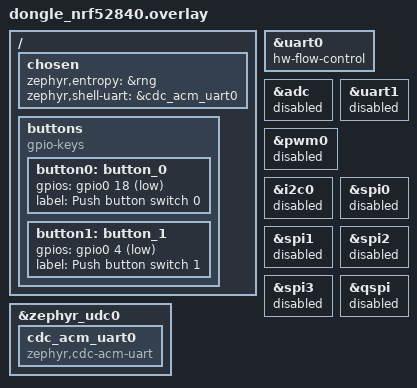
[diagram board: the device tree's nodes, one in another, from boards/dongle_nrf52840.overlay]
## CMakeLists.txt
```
#
# Copyright (c) 2020 Nordic Semiconductor ASA
#
# SPDX-License-Identifier: LicenseRef-Nordic-5-Clause
#

cmake_minimum_required(VERSION 3.20.0)

find_package(Zephyr REQUIRED HINTS $ENV{ZEPHYR_BASE})

project(thread_dongle_server_usb)

FILE(GLOB app_sources src/*.c)
# NORDIC SDK APP START
target_sources(app PRIVATE ${app_sources})

target_include_directories(app PRIVATE interface)
# NORDIC SDK APP END
```

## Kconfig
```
#
# Copyright (c) 2020 Nordic Semiconductor ASA
#
# SPDX-License-Identifier: LicenseRef-Nordic-5-Clause
#

menu "Zephyr Kernel"
source "Kconfig.zephyr"
endmenu

module = COAP_SERVER
module-str = CoAP server
source "${ZEPHYR_BASE}/subsys/logging/Kconfig.template.log_config"

module = OT_COAP_UTILS
module-str = OpenThread CoAP utils
source "${ZEPHYR_BASE}/subsys/logging/Kconfig.template.log_config"

config UART_LOG_ENABLE
    bool "Enable UART logging"
    default n
    help
      Enable this option to activate logging over UART
```

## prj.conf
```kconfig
#
# Copyright (c) 2020 Nordic Semiconductor
#
# SPDX-License-Identifier: LicenseRef-Nordic-5-Clause
#

# nRF board library
CONFIG_DK_LIBRARY=y 

# Enable OpenThread CoAP support API
CONFIG_OPENTHREAD_COAP=y 

# Network sockets
CONFIG_NET_SOCKETS=y
CONFIG_NET_SOCKETS_POSIX_NAMES=y
CONFIG_NET_SOCKETS_POLL_MAX=4

# Same network Master Key for client and server
CONFIG_OPENTHREAD_NETWORKKEY="00:11:22:33:44:55:66:77:88:99:aa:bb:cc:dd:ee:ff"

# L2 OpenThread enabling
CONFIG_NET_L2_OPENTHREAD=y

# Generic networking options
CONFIG_NETWORKING=y

CONFIG_MBEDTLS_SHA1_C=n
CONFIG_FPU=y

# UART conf
CONFIG_SERIAL=y
CONFIG_UART_INTERRUPT_DRIVEN=y
CONFIG_UART_ASYNC_API=y
CONFIG_UART_LOG_ENABLE=n
```

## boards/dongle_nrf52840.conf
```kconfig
#
# Copyright (c) 2016-2023 Makerdiary
#
# SPDX-License-Identifier: Apache-2.0
#

# USB subsystem configuration
CONFIG_USB_DEVICE_STACK=y
CONFIG_USB_DEVICE_PRODUCT="Thread Border Router USB"
CONFIG_USB_DEVICE_INITIALIZE_AT_BOOT=y
```

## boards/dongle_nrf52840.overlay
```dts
/* Copyright (c) 2020 Nordic Semiconductor ASA
 *
 * SPDX-License-Identifier: LicenseRef-Nordic-5-Clause
 */

&uart0 {
    status = "okay";
    hw-flow-control;
};

&zephyr_udc0 {
    cdc_acm_uart0: cdc_acm_uart0 {
        compatible = "zephyr,cdc-acm-uart";
    };
};

/ {
    /*
    * In some default configurations within the nRF Connect SDK,
    * e.g. on nRF52840, the chosen zephyr,entropy node is &cryptocell.
    * This devicetree overlay ensures that default is overridden wherever it
    * is set, as this application uses the RNG node for entropy exclusively.
    */
    chosen {
        zephyr,entropy = &rng;
        zephyr,shell-uart = &cdc_acm_uart0;
    };
    buttons {
        compatible = "gpio-keys";
        button0: button_0 {
            gpios = <&gpio0 18 (GPIO_PULL_UP | GPIO_ACTIVE_LOW)>;
            label = "Push button switch 0";
        };
        button1: button_1 {
            gpios = <&gpio0 4 (GPIO_PULL_UP | GPIO_ACTIVE_LOW)>;
            label = "Push button switch 1";
        };
    };
};

&adc {
    status = "disabled";
};
&uart1 {
    status = "disabled";
};
&pwm0 {
    status = "disabled";
};
&i2c0 {
    status = "disabled";
};
&spi0 {
    status = "disabled";
};
&spi1 {
    status = "disabled";
};
&spi2 {
    status = "disabled";
};
&spi3 {
    status = "disabled";
};
&qspi {
    status = "disabled";
};
```

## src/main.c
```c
/*
 * Copyright (c) 2020 Nordic Semiconductor ASA
 * Copyright (c) 2016-2023 Makerdiary
 *
 * SPDX-License-Identifier: LicenseRef-Nordic-5-Clause
 */

#include <zephyr/kernel.h>
#include <dk_buttons_and_leds.h>

#include "coap_server.h"
#include "uart_interface.h"

#define SLEEP_TIME_MS   100

//Callback for button press
static void on_button_changed(uint32_t button_state, uint32_t has_changed)
{
    // TODO: What to do if button pressed ???
    uint32_t buttons = button_state & has_changed;
    if (buttons & DK_BTN1_MSK) {
        print_ressources_status();
        //  switch_wifi_status();
        //  switch_presence_status();
        //  switch_electrical_status();
    }    
}

int main(void)
{   int ret;

    ret = init_uart();
    if (ret) {
        print_uart("[ERROR]: UART init \r\n");
        return 1;
    } 
    print_uart("[LOG]: UART initialized\r\n");

    print_uart("[LOG]: Green WiFi Thread Dongle .\r\n");
	print_uart("[LOG]: Developed by Nicolas Hernandez\r\n");
    print_uart("[LOG]: nicolas.hernandez@orange.com\r\n");

    ret = dk_leds_init();
    if (ret) {
        print_uart("[ERROR]: leds init \r\n");
        return 1;
    }
    print_uart("[LOG]: Leds initialized\r\n");

    ret = dk_buttons_init(on_button_changed);
    if (ret) {
        print_uart("[ERROR]: buttons init \r\n");
        return 1;
    }
    print_uart("[LOG]: Butttons initialized\r\n");

    ret = init_coap_thread();
    if (ret) {
        print_uart("[ERROR]: Thread init \r\n");
        return 1;
    }    
    print_uart("[LOG]: Thread initialized\r\n");

    // loop forever waiting for uart messages
    read_forever();
    return 0;
}
```

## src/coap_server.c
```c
/*
 * Copyright (c) 2020 Nordic Semiconductor ASA
 * Copyright (c) 2016-2023 Makerdiary
 *
 * SPDX-License-Identifier: LicenseRef-Nordic-5-Clause
 */

#include "ot_coap_utils.h"

#define LED_ON_TIME_MS 250
char uart_print_buff[50]; 

// Callback for commands topic
static void on_commands_request(uint8_t* msg_buf, uint8_t msg_len)
{   
    // Empty the string
    uart_print_buff[0] = '\0';

    print_uart("[LOG]: COAP - Commands msg received: ");
    for (int i = 0; i <= msg_len; i++) {
        uart_print_buff[i] = msg_buf[i];
    }
    uart_print_buff[msg_len] = '\0';
    print_uart(uart_print_buff);

    dk_set_led_on(COMMANDS_MSG_LED);
    k_msleep(LED_ON_TIME_MS);
    dk_set_led_off(COMMANDS_MSG_LED);  
    
}

// Callback for ressources status topic
static void on_ressource_status_request()
{
    dk_set_led_on(RESSOURCES_STATUS_MSG_LED);
    k_msleep(LED_ON_TIME_MS);
    dk_set_led_off(RESSOURCES_STATUS_MSG_LED);    
}

// Callback for wifi topic
static void on_wifi_status_request()
{
    dk_set_led_on(RESSOURCES_STATUS_MSG_LED);
    k_msleep(LED_ON_TIME_MS);
    dk_set_led_off(RESSOURCES_STATUS_MSG_LED);    
}

// Callback for presence topic
static void on_presence_status_request()
{
    dk_set_led_on(RESSOURCES_STATUS_MSG_LED);
    k_msleep(LED_ON_TIME_MS);
    dk_set_led_off(RESSOURCES_STATUS_MSG_LED);    
}

// Callback for electrical topic
static void on_electrical_status_request()
{
    dk_set_led_on(RESSOURCES_STATUS_MSG_LED);
    k_msleep(LED_ON_TIME_MS);
    dk_set_led_off(RESSOURCES_STATUS_MSG_LED);    
}

// Callback for power strip topic
static void on_power_strip_status_request()
{
    dk_set_led_on(RESSOURCES_STATUS_MSG_LED);
    k_msleep(LED_ON_TIME_MS);
    dk_set_led_off(RESSOURCES_STATUS_MSG_LED);    
}

static void on_thread_state_changed(otChangedFlags flags, struct openthread_context *ot_context,
                    void *user_data)
{
    if (flags & OT_CHANGED_THREAD_ROLE) {
        switch (otThreadGetDeviceRole(ot_context->instance)) {
        case OT_DEVICE_ROLE_CHILD:
        case OT_DEVICE_ROLE_ROUTER:
        case OT_DEVICE_ROLE_LEADER:
            dk_set_led_on(OT_CONNECTION_LED);
            break;

        case OT_DEVICE_ROLE_DISABLED:
        case OT_DEVICE_ROLE_DETACHED:
        default:
            dk_set_led_off(OT_CONNECTION_LED);
            break;
        }
    }
}

static struct openthread_state_changed_cb ot_state_chaged_cb = { .state_changed_cb =
                                     on_thread_state_changed };


int init_coap_thread()
{
    int ret;
    ret = ot_coap_init(
        &on_ressource_status_request, 
        &on_wifi_status_request, 
        &on_presence_status_request, 
        &on_electrical_status_request, 
        &on_power_strip_status_request, 
        &on_commands_request
    );
    
    if (ret) {
        print_uart("[ERROR]: Init OpenThread CoAP\r\n: ");
        return 1;
    }

    openthread_state_changed_cb_register(openthread_get_default_context(), &ot_state_chaged_cb);
    openthread_start(openthread_get_default_context());    

    return 0;

}
```

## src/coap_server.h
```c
#ifndef COAP_SERVER_H
#define COAP_SERVER_H

#include <zephyr/net/openthread.h>
#include <openthread/thread.h>
#include <zephyr/kernel.h>
#include <dk_buttons_and_leds.h>

// Function declarations
static void on_commands_request(uint8_t* msg_buf, uint8_t msg_len);
static void on_ressource_status_request(void);
static void on_wifi_status_request(void);
static void on_presence_status_request(void);
static void on_electrical_status_request(void);
static void on_power_strip_status_request();
static void on_thread_state_changed(otChangedFlags flags, struct openthread_context *ot_context, void *user_data);
int init_coap_thread();

#endif 
```

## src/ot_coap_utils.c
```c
/*
 * Copyright (c) 2020 Nordic Semiconductor ASA
 *
 * SPDX-License-Identifier: LicenseRef-Nordic-5-Clause
 */

#include "ot_coap_utils.h"
#include "uart_interface.h"

uint8_t msg_buf[MSG_BUFF_SIZE];
uint16_t msg_len = 0; 
char print_buff[50]; 

struct server_context {
    struct otInstance *ot;
    ressources_status_request_callback_t on_ressources_status_request;
    wifi_status_request_callback_t on_wifi_status_request;
    presence_status_request_callback_t on_presence_status_request;
    electrical_status_request_callback_t on_eletrical_status_request;
    power_strip_status_request_callback_t on_power_strip_status_request;
    commands_request_callback_t on_commands_request;
    bool wifi_status;
    bool presence_status;
    bool electrical_status;
    bool power_strip_r1_status;
    bool power_strip_r2_status;
    bool power_strip_r3_status;
    bool power_strip_r4_status;
};

static struct server_context srv_context = {
    .ot = NULL,    
    .on_ressources_status_request = NULL,
    .on_wifi_status_request = NULL,
    .on_eletrical_status_request= NULL,
    .on_commands_request = NULL,
    .wifi_status = NULL,
    .presence_status = NULL,
    .electrical_status = NULL,
    .power_strip_r1_status = NULL,
    .power_strip_r2_status = NULL,
    .power_strip_r3_status = NULL,
    .power_strip_r4_status = NULL,
};

/**@brief Definition of CoAP resources for orchestrator status resources. */
static otCoapResource ressources_status_resource = {
    .mUriPath = RESSOURCES_URI_PATH,
    .mHandler = NULL,
    .mContext = NULL,
    .mNext = NULL,
};

/**@brief Definition of CoAP resources for wifi status resources. */
static otCoapResource wifi_status_resource = {
    .mUriPath = WIFI_URI_PATH,
    .mHandler = NULL,
    .mContext = NULL,
    .mNext = NULL,
};

/**@brief Definition of CoAP resources for presence status resources. */
static otCoapResource presence_status_resource = {
    .mUriPath = PRESENCE_URI_PATH,
    .mHandler = NULL,
    .mContext = NULL,
    .mNext = NULL,
};

/**@brief Definition of CoAP resources for electrical status resources. */
static otCoapResource electrical_status_resource = {
    .mUriPath = ELECTRIC_URI_PATH,
    .mHandler = NULL,
    .mContext = NULL,
    .mNext = NULL,
};

/**@brief Definition of CoAP resources for power_strip status resources. */
static otCoapResource power_strip_status_resource = {
    .mUriPath = POWER_STRIP_URI_PATH,
    .mHandler = NULL,
    .mContext = NULL,
    .mNext = NULL,
};

/**@brief Definition of CoAP resources for commands. */
static otCoapResource commands_resource = {
    .mUriPath = COMMANDS_URI_PATH,
    .mHandler = NULL,
    .mContext = NULL,
    .mNext = NULL,
};

void set_wifi_status(bool new_status){
    srv_context.wifi_status = new_status;
    snprintf(print_buff, sizeof(print_buff), "%s%s\r\n", "[LOG]: New wifi status ", srv_context.wifi_status ? "true" : "false");
    print_uart(print_buff);
}
void set_presence_status(bool new_status){
    srv_context.presence_status = new_status;
    snprintf(print_buff, sizeof(print_buff), "%s%s\r\n", "[LOG]: New presence status ", srv_context.presence_status ? "true" : "false");
    print_uart(print_buff);
}
void set_electrical_status(bool new_status){
    srv_context.electrical_status = new_status;
    snprintf(print_buff, sizeof(print_buff), "%s%s\r\n", "[LOG]: New electrical status ", srv_context.electrical_status ? "true" : "false");
    print_uart(print_buff);
}

void set_power_strip_status(bool new_r1_status, bool new_r2_status, bool new_r3_status, bool new_r4_status){
    srv_context.power_strip_r1_status = new_r1_status;
    srv_context.power_strip_r2_status = new_r2_status;
    srv_context.power_strip_r3_status = new_r3_status;
    srv_context.power_strip_r4_status = new_r4_status;
    snprintf(print_buff, sizeof(print_buff), "%s%d%d%d%d\r\n", "[LOG]: New power strip status ", srv_context.power_strip_r1_status, srv_context.power_strip_r2_status, srv_context.power_strip_r3_status, srv_context.power_strip_r4_status );
    print_uart(print_buff);
}

void print_ressources_status(void){
    print_uart("[LOG]: Server Ressources   \r\n");
    snprintf(print_buff, sizeof(print_buff), "%s%s\r\n", "[LOG]:     Wifi status ", srv_context.wifi_status ? "true" : "false");
    print_uart(print_buff);     
    snprintf(print_buff, sizeof(print_buff), "%s%s\r\n", "[LOG]:     Presence status ", srv_context.presence_status ? "true" : "false");
    print_uart(print_buff);
    snprintf(print_buff, sizeof(print_buff), "%s%s\r\n", "[LOG]:     Electrical status ", srv_context.electrical_status ? "true" : "false");
    print_uart(print_buff);
    snprintf(print_buff, sizeof(print_buff), "%s%d%d%d%d\r\n", "[LOG]:     Power strip status ", srv_context.power_strip_r1_status, srv_context.power_strip_r2_status, srv_context.power_strip_r3_status, srv_context.power_strip_r4_status );
    print_uart(print_buff);
}

static otError ressources_status_response_send(otMessage *request_message,
                      const otMessageInfo *message_info)
{
    otError error = OT_ERROR_NO_BUFS;
    otMessage *response;    

    response = otCoapNewMessage(srv_context.ot, NULL);
    if (response == NULL) {
        goto end;
    }

    otCoapMessageInit(response, OT_COAP_TYPE_NON_CONFIRMABLE,
              OT_COAP_CODE_CONTENT);

    error = otCoapMessageSetToken(
        response, otCoapMessageGetToken(request_message),
        otCoapMessageGetTokenLength(request_message));
    if (error != OT_ERROR_NONE) {
        goto end;
    }

    error = otCoapMessageSetPayloadMarker(response);
    if (error != OT_ERROR_NONE) {
        goto end;
    }

    // Append wifi status to payload
    uint8_t *wifi_payload = srv_context.wifi_status ? "wifi:1" : "wifi:0";
    uint16_t wifi_payload_size = strlen(wifi_payload);
    
    // Append ressources status to payload
    uint8_t *presence_payload = srv_context.presence_status ? " prs:1" : " prs:0";
    uint16_t presence_payload_size = strlen(presence_payload);

    // Append electrical status to payload
    uint8_t *electrical_payload = srv_context.electrical_status ? " ele:1" : " ele:0";
    uint16_t electrical_payload_size = strlen(electrical_payload);

    // Append power strip status to payload  
    uint8_t power_strip_payload[] = " outlet:XXXX";
    uint8_t r1_status_payload = srv_context.power_strip_r1_status ? '1':'0';
    uint8_t r2_status_payload = srv_context.power_strip_r2_status ? '1':'0';
    uint8_t r3_status_payload = srv_context.power_strip_r3_status ? '1':'0';
    uint8_t r4_status_payload = srv_context.power_strip_r4_status ? '1':'0';
    power_strip_payload[8] = r1_status_payload;   
    power_strip_payload[9] = r2_status_payload;   
    power_strip_payload[10] = r3_status_payload;   
    power_strip_payload[11] = r4_status_payload;   
    uint16_t power_strip_payload_size = strlen(power_strip_payload);

    // Get payload size
    uint16_t payload_size = wifi_payload_size + presence_payload_size + electrical_payload_size + power_strip_payload_size + 1;
    uint8_t *payload = (uint8_t*) malloc(payload_size * sizeof(uint8_t));

    if(payload == NULL) {
        print_uart("[ERROR]: Error in payload memory alocation \r\n");    
        error = OT_ERROR_FAILED; 
        goto end;
    }

    // Concatenate payload
    uint16_t new_index = 0;
    for(uint16_t i = 0; i < payload_size - 1; i++){
        if(i < wifi_payload_size){   
            payload[i] = wifi_payload[i];
        }
        if((i >= wifi_payload_size) && (i < wifi_payload_size + presence_payload_size)){
            new_index = i - wifi_payload_size;
            payload[i] = presence_payload[new_index];
        }
        if((i >= wifi_payload_size + presence_payload_size) && (i < wifi_payload_size + presence_payload_size + electrical_payload_size)){
            new_index = i - wifi_payload_size - presence_payload_size;
            payload[i] = electrical_payload[new_index];
        }
        if(i >= wifi_payload_size + presence_payload_size + electrical_payload_size){   
            new_index = i - wifi_payload_size - presence_payload_size - electrical_payload_size;
            payload[i] = power_strip_payload[new_index];
        }
    }

    payload[payload_size - 1 ] = '\0';
    snprintf(print_buff, sizeof(print_buff), "%s%s\r\n", "[LOG]: Sending response payload: ", payload);
    print_uart(print_buff);

    error = otMessageAppend(response, payload, payload_size);
    if (error != OT_ERROR_NONE) {
        goto end;
    }

    error = otCoapSendResponse(srv_context.ot, response, message_info);

end:
    if (error != OT_ERROR_NONE && response != NULL) {
        otMessageFree(response);
    }

    free(payload);
    return error;
}

static void ressources_status_request_handler(void *context, otMessage *message,
                     const otMessageInfo *message_info)
{
    otError error;
    otMessageInfo msg_info;

    ARG_UNUSED(context);
    
    print_uart("[LOG]: Received ressources status request\r\n");

    if ((otCoapMessageGetType(message) == OT_COAP_TYPE_NON_CONFIRMABLE) &&
        (otCoapMessageGetCode(message) == OT_COAP_CODE_GET)) {
        msg_info = *message_info;
        memset(&msg_info.mSockAddr, 0, sizeof(msg_info.mSockAddr));

        error = ressources_status_response_send(message, &msg_info);
        if (error == OT_ERROR_NONE) {
            srv_context.on_ressources_status_request();
        }
    }
}

static otError wifi_status_response_send(otMessage *request_message,
                      const otMessageInfo *message_info)
{
    otError error = OT_ERROR_NO_BUFS;
    otMessage *response;    

    response = otCoapNewMessage(srv_context.ot, NULL);
    if (response == NULL) {
        goto end;
    }

    otCoapMessageInit(response, OT_COAP_TYPE_NON_CONFIRMABLE,
              OT_COAP_CODE_CONTENT);

    error = otCoapMessageSetToken(
        response, otCoapMessageGetToken(request_message),
        otCoapMessageGetTokenLength(request_message));
    if (error != OT_ERROR_NONE) {
        goto end;
    }

    error = otCoapMessageSetPayloadMarker(response);
    if (error != OT_ERROR_NONE) {
        goto end;
    }

    // Append wifi status to payload
    uint8_t *payload = srv_context.wifi_status ? "wifi:1" : "wifi:0";
    uint16_t payload_size = strlen(payload) + 1;

    snprintf(print_buff, sizeof(print_buff), "%s%s\r\n", "[LOG]: Wifi response payload: ", payload);
    print_uart(print_buff);

    error = otMessageAppend(response, payload, payload_size);
    if (error != OT_ERROR_NONE) {
        goto end;
    }

    error = otCoapSendResponse(srv_context.ot, response, message_info);

end:
    if (error != OT_ERROR_NONE && response != NULL) {
        otMessageFree(response);
    }

    return error;
}

static void wifi_status_request_handler(void *context, otMessage *message,
                     const otMessageInfo *message_info)
{
    otError error;
    otMessageInfo msg_info;

    ARG_UNUSED(context);

    print_uart("LOG]: Received wifi status request\r\n");

    if ((otCoapMessageGetType(message) == OT_COAP_TYPE_NON_CONFIRMABLE) &&
        (otCoapMessageGetCode(message) == OT_COAP_CODE_GET)) {
        msg_info = *message_info;
        memset(&msg_info.mSockAddr, 0, sizeof(msg_info.mSockAddr));

        error = wifi_status_response_send(message, &msg_info);
        if (error == OT_ERROR_NONE) {
            srv_context.on_ressources_status_request();
        }
    }
}

static otError presence_status_response_send(otMessage *request_message,
                      const otMessageInfo *message_info)
{
    otError error = OT_ERROR_NO_BUFS;
    otMessage *response;    

    response = otCoapNewMessage(srv_context.ot, NULL);
    if (response == NULL) {
        goto end;
    }

    otCoapMessageInit(response, OT_COAP_TYPE_NON_CONFIRMABLE,
              OT_COAP_CODE_CONTENT);

    error = otCoapMessageSetToken(
        response, otCoapMessageGetToken(request_message),
        otCoapMessageGetTokenLength(request_message));
    if (error != OT_ERROR_NONE) {
        goto end;
    }

    error = otCoapMessageSetPayloadMarker(response);
    if (error != OT_ERROR_NONE) {
        goto end;
    }

    // Append presence status to payload
    uint8_t *payload = srv_context.presence_status ? "prs:1" : "prs:0";
    uint16_t payload_size = strlen(payload) + 1;

    snprintf(print_buff, sizeof(print_buff), "%s%s\r\n", "[LOG]: Presence response payload: ", payload);
    print_uart(print_buff);

    error = otMessageAppend(response, payload, payload_size);
    if (error != OT_ERROR_NONE) {
        goto end;
    }

    error = otCoapSendResponse(srv_context.ot, response, message_info);

end:
    if (error != OT_ERROR_NONE && response != NULL) {
        otMessageFree(response);
    }

    return error;
}

static void presence_status_request_handler(void *context, otMessage *message,
                     const otMessageInfo *message_info)
{
    otError error;
    otMessageInfo msg_info;

    ARG_UNUSED(context);

    print_uart("[LOG]: Received presence status request\r\n");

    if ((otCoapMessageGetType(message) == OT_COAP_TYPE_NON_CONFIRMABLE) &&
        (otCoapMessageGetCode(message) == OT_COAP_CODE_GET)) {
        msg_info = *message_info;
        memset(&msg_info.mSockAddr, 0, sizeof(msg_info.mSockAddr));

        error = presence_status_response_send(message, &msg_info);
        if (error == OT_ERROR_NONE) {
            srv_context.on_ressources_status_request();
        }
    }
}

static otError electrical_status_response_send(otMessage *request_message,
                      const otMessageInfo *message_info)
{
    otError error = OT_ERROR_NO_BUFS;
    otMessage *response;    

    response = otCoapNewMessage(srv_context.ot, NULL);
    if (response == NULL) {
        goto end;
    }

    otCoapMessageInit(response, OT_COAP_TYPE_NON_CONFIRMABLE,
              OT_COAP_CODE_CONTENT);

    error = otCoapMessageSetToken(
        response, otCoapMessageGetToken(request_message),
        otCoapMessageGetTokenLength(request_message));
    if (error != OT_ERROR_NONE) {
        goto end;
    }

    error = otCoapMessageSetPayloadMarker(response);
    if (error != OT_ERROR_NONE) {
        goto end;
    }

    // Append electrical status to payload
    uint8_t *payload = srv_context.electrical_status ? "ele:1" : "ele:0";
    uint16_t payload_size = strlen(payload) + 1;

    snprintf(print_buff, sizeof(print_buff), "%s%s\r\n", "[LOG]: Electrical response payload: ", payload);
    print_uart(print_buff);

    error = otMessageAppend(response, payload, payload_size);
    if (error != OT_ERROR_NONE) {
        goto end;
    }

    error = otCoapSendResponse(srv_context.ot, response, message_info);

end:
    if (error != OT_ERROR_NONE && response != NULL) {
        otMessageFree(response);
    }

    return error;
}

static void electrical_status_request_handler(void *context, otMessage *message,
                     const otMessageInfo *message_info)
{
    otError error;
    otMessageInfo msg_info;

    ARG_UNUSED(context);

    print_uart("[LOG]: Received electrical status request\r\n");

    if ((otCoapMessageGetType(message) == OT_COAP_TYPE_NON_CONFIRMABLE) &&
        (otCoapMessageGetCode(message) == OT_COAP_CODE_GET)) {
        msg_info = *message_info;
        memset(&msg_info.mSockAddr, 0, sizeof(msg_info.mSockAddr));

        error = electrical_status_response_send(message, &msg_info);
        if (error == OT_ERROR_NONE) {
            srv_context.on_ressources_status_request();
        }
    }
}

static otError power_strip_status_response_send(otMessage *request_message,
                      const otMessageInfo *message_info)
{
    otError error = OT_ERROR_NO_BUFS;
    otMessage *response;    

    response = otCoapNewMessage(srv_context.ot, NULL);
    if (response == NULL) {
        goto end;
    }

    otCoapMessageInit(response, OT_COAP_TYPE_NON_CONFIRMABLE,
              OT_COAP_CODE_CONTENT);

    error = otCoapMessageSetToken(
        response, otCoapMessageGetToken(request_message),
        otCoapMessageGetTokenLength(request_message));
    if (error != OT_ERROR_NONE) {
        goto end;
    }

    error = otCoapMessageSetPayloadMarker(response);
    if (error != OT_ERROR_NONE) {
        goto end;
    }

    // Append power strip status to payload
    uint8_t payload[] = " outlet:XXXX";
    payload[8] = srv_context.power_strip_r1_status ? '1':'0';   
    payload[9] = srv_context.power_strip_r2_status ? '1':'0';   
    payload[10] = srv_context.power_strip_r3_status ? '1':'0';   
    payload[11] = srv_context.power_strip_r4_status ? '1':'0';   
    uint16_t payload_size = strlen(payload);    

    snprintf(print_buff, sizeof(print_buff), "%s%s\r\n", "[LOG]: Power Strip response payload: ", payload);
    print_uart(print_buff);

    error = otMessageAppend(response, payload, payload_size);
    if (error != OT_ERROR_NONE) {
        goto end;
    }

    error = otCoapSendResponse(srv_context.ot, response, message_info);

end:
    if (error != OT_ERROR_NONE && response != NULL) {
        otMessageFree(response);
    }

    return error;
}

static void power_strip_status_request_handler(void *context, otMessage *message,
                     const otMessageInfo *message_info)
{
    otError error;
    otMessageInfo msg_info;

    ARG_UNUSED(context);

    print_uart("[LOG]: Received power strip status request\r\n");

    if ((otCoapMessageGetType(message) == OT_COAP_TYPE_NON_CONFIRMABLE) &&
        (otCoapMessageGetCode(message) == OT_COAP_CODE_GET)) {
        msg_info = *message_info;
        memset(&msg_info.mSockAddr, 0, sizeof(msg_info.mSockAddr));

        error = power_strip_status_response_send(message, &msg_info);
        if (error == OT_ERROR_NONE) {
            srv_context.on_ressources_status_request();
        }
    }
}

static otError commands_msg_response_send(otMessage *request_message,
                      const otMessageInfo *message_info)
{
    otError error = OT_ERROR_NO_BUFS;
    otMessage *response;    

    response = otCoapNewMessage(srv_context.ot, NULL);
    if (response == NULL) {
        goto end;
    }

    otCoapMessageInit(response, OT_COAP_TYPE_NON_CONFIRMABLE,
              OT_COAP_CODE_CONTENT);

    error = otCoapMessageSetToken(
        response, otCoapMessageGetToken(request_message),
        otCoapMessageGetTokenLength(request_message));
    if (error != OT_ERROR_NONE) {
        goto end;
    }

    error = otCoapMessageSetPayloadMarker(response);
    if (error != OT_ERROR_NONE) {
        goto end;
    }

    // Append presence status to payload
    uint8_t *payload = "CMD:OK";
    uint16_t payload_size = strlen(payload) + 1;

    error = otMessageAppend(response, payload, payload_size);
    if (error != OT_ERROR_NONE) {
        goto end;
    }

    error = otCoapSendResponse(srv_context.ot, response, message_info);

end:
    if (error != OT_ERROR_NONE && response != NULL) {
        otMessageFree(response);
    }

    return error;
}

static void commands_request_handler(void *context, otMessage *message,
                  const otMessageInfo *message_info)
{

    otError error;
    otMessageInfo msg_info;

    ARG_UNUSED(context);

    print_uart("[LOG]: Commands message received\r\n");

    ARG_UNUSED(context);   

    if (otCoapMessageGetType(message) != OT_COAP_TYPE_NON_CONFIRMABLE) {
        print_uart("[ERROR]: Commands handler - Unexpected type of message\r\n");
        goto end;
    }

    if (otCoapMessageGetCode(message) != OT_COAP_CODE_PUT) {
        print_uart("[ERROR]: Commands handler - Unexpected CoAP code\r\n");
        goto end;
    }

    msg_info = *message_info;
    memset(&msg_info.mSockAddr, 0, sizeof(msg_info.mSockAddr));

    error = commands_msg_response_send(message, &msg_info);
    if (error == OT_ERROR_NONE) {
        msg_len = otMessageRead(message, otMessageGetOffset(message), msg_buf, MSG_BUFF_SIZE);
        srv_context.on_commands_request(&msg_buf, msg_len);
    }   
end:
    return;
}

static void coap_default_handler(void *context, otMessage *message,
                 const otMessageInfo *message_info)
{
    print_uart("[LOG]: Uncontext msg received\r\n");
    ARG_UNUSED(context);
    ARG_UNUSED(message);
    ARG_UNUSED(message_info);
}

int ot_coap_init(
    ressources_status_request_callback_t on_ressources_status_request,
    wifi_status_request_callback_t on_wifi_status_request,
    presence_status_request_callback_t on_presence_status_request,
    electrical_status_request_callback_t on_electrical_status_request,
    power_strip_status_request_callback_t on_power_strip_status_request,
    commands_request_callback_t on_commands_request  
)
{
    otError error;

    srv_context.wifi_status = false;
    srv_context.presence_status = false;
    srv_context.electrical_status = false;

    srv_context.on_ressources_status_request = on_ressources_status_request;
    srv_context.on_wifi_status_request = on_wifi_status_request;
    srv_context.on_presence_status_request = on_presence_status_request;
    srv_context.on_eletrical_status_request = on_electrical_status_request;
    srv_context.on_power_strip_status_request = on_power_strip_status_request;
    srv_context.on_commands_request = on_commands_request;    

    srv_context.ot = openthread_get_default_instance();
    if (!srv_context.ot) {
        error = OT_ERROR_FAILED;
        goto end;
    }

    ressources_status_resource.mContext = srv_context.ot;
    ressources_status_resource.mHandler = ressources_status_request_handler;

    wifi_status_resource.mContext = srv_context.ot;
    wifi_status_resource.mHandler = wifi_status_request_handler;

    presence_status_resource.mContext = srv_context.ot;
    presence_status_resource.mHandler = presence_status_request_handler;

    electrical_status_resource.mContext = srv_context.ot;
    electrical_status_resource.mHandler = electrical_status_request_handler;

    power_strip_status_resource.mContext = srv_context.ot;
    power_strip_status_resource.mHandler = power_strip_status_request_handler;

    commands_resource.mContext = srv_context.ot;
    commands_resource.mHandler = commands_request_handler;

    otCoapSetDefaultHandler(srv_context.ot, coap_default_handler, NULL);
    otCoapAddResource(srv_context.ot, &commands_resource);
    otCoapAddResource(srv_context.ot, &ressources_status_resource);
    otCoapAddResource(srv_context.ot, &wifi_status_resource);
    otCoapAddResource(srv_context.ot, &presence_status_resource);
    otCoapAddResource(srv_context.ot, &electrical_status_resource);
    otCoapAddResource(srv_context.ot, &power_strip_status_resource);

    error = otCoapStart(srv_context.ot, COAP_PORT);
    if (error != OT_ERROR_NONE) {
        goto end;
    }

end:
    return error == OT_ERROR_NONE ? 0 : 1;
}
```

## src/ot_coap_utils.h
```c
/*
 * Copyright (c) 2020 Nordic Semiconductor ASA
 *
 * SPDX-License-Identifier: LicenseRef-Nordic-5-Clause
 */

#ifndef __OT_COAP_UTILS_H__
#define __OT_COAP_UTILS_H__

#include <thread_dongle_interface.h>
#include <zephyr/net/net_pkt.h>
#include <zephyr/net/net_l2.h>
#include <zephyr/net/openthread.h>
#include <openthread/coap.h>
#include <openthread/ip6.h>
#include <openthread/message.h>
#include <openthread/thread.h>

/**@brief Type definition of the function used to handle commands resource msg.
 */
typedef void (*commands_request_callback_t)(uint8_t* msg_buf, uint8_t msg_len);
/**@brief Type definition of the function used to handle ressources status resource msg.
 */
typedef void (*ressources_status_request_callback_t)();
/**@brief Type definition of the function used to handle wifi status resource msg.
 */
typedef void (*wifi_status_request_callback_t)();
/**@brief Type definition of the function used to handle presence status resource msg.
 */
typedef void (*presence_status_request_callback_t)();

/**@brief Type definition of the function used to handle electrical status resource msg.
 */
typedef void (*electrical_status_request_callback_t)();

/**@brief Type definition of the function used to handle power strip status resource msg.
 */
typedef void (*power_strip_status_request_callback_t)();

int ot_coap_init(
    ressources_status_request_callback_t on_ressources_status_request, 
    wifi_status_request_callback_t on_wifi_status_request, 
    presence_status_request_callback_t on_presence_status_request,
    electrical_status_request_callback_t on_electrical_status_request, 
    power_strip_status_request_callback_t on_power_strip_status_request, 
    commands_request_callback_t on_commands_request
);

/**@brief Type definition of the function used to set wifi status resource msg.
 */
void set_wifi_status(bool new_status);
/**@brief Type definition of the function used to set presence status resource msg.
 */
void set_presence_status(bool new_status);
/**@brief Type definition of the function used to set electrical status resource msg.
 */
void set_electrical_status(bool new_status);
/**@brief Type definition of the function used to set power strip status resource msg.
 */
void set_power_strip_status(bool new_r1_status, bool new_r2_status, bool new_r3_status, bool new_r4_status);

/**@brief Type definition of the function used to print current status.
 */
void print_ressources_status();

#endif
```

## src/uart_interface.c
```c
/*
 * Copyright (c) 2022 Libre Solar Technologies GmbH
 *
 * SPDX-License-Identifier: Apache-2.0
 */
#include "uart_interface.h"
#include "ot_coap_utils.h"

/* change this to any other UART peripheral if desired */
#define UART_DEVICE_NODE DT_CHOSEN(zephyr_shell_uart)

#define MSG_SIZE 32

/* queue to store up to 10 messages (aligned to 4-byte boundary) */
K_MSGQ_DEFINE(uart_msgq, MSG_SIZE, 10, 4);

static const struct device *const uart_dev = DEVICE_DT_GET(UART_DEVICE_NODE);

/* receive buffer used in UART ISR callback */
static char rx_buf[MSG_SIZE];
static int rx_buf_pos;
char tx_buff[50]; 

/*UART logging enable*/
int log_in_uart = 1;

/*
 * Read characters from UART until line end is detected. Afterwards push the
 * data to the message queue.
 */
void serial_cb(const struct device *dev, void *user_data)
{
	uint8_t c;

	if (!uart_irq_update(uart_dev)) {
		return;
	}

	if (!uart_irq_rx_ready(uart_dev)) {
		return;
	}

	/* read until FIFO empty */
	while (uart_fifo_read(uart_dev, &c, 1) == 1) {
		if ((c == '\n' || c == '\r') && rx_buf_pos > 0) {
			/* terminate string */
			rx_buf[rx_buf_pos] = '\0';

			/* if queue is full, message is silently dropped */
			k_msgq_put(&uart_msgq, &rx_buf, K_NO_WAIT);

			/* reset the buffer (it was copied to the msgq) */
			for( int i =0; i < MSG_SIZE; i++ ){
				rx_buf[i] = NULL;
			}  
			rx_buf_pos = 0;

		} else if (rx_buf_pos < (sizeof(rx_buf) - 1)) {
			rx_buf[rx_buf_pos++] = c;
		}
		/* else: characters beyond buffer size are dropped */
	}
}

/*
 * Print a null-terminated string character by character to the UART interface
 */
void print_uart(char *buf)
{
	int msg_len = strlen(buf);

	const char *log_str = "LOG";
	const char *error_str = "ERROR";
	int print_msg = 1;

	/*If LOG or ERROR in message only print if UART_LOG=y*/
	if((strstr(buf, log_str) != NULL) || (strstr(buf, error_str) != NULL)){
		if(!log_in_uart){
			print_msg = 0;
		}	
	}
	
	if(print_msg){
		for (int i = 0; i < msg_len; i++) {
		uart_poll_out(uart_dev, buf[i]);
		}
	}	
}

int init_uart()
{	
	/* Enable/disable UART logging*/
	#ifdef CONFIG_UART_LOG_ENABLE
		log_in_uart = 1; // Logging is enabled
	#else
		log_in_uart = 0; // Logging is disabled
	#endif

	if (!device_is_ready(uart_dev)) {
		print_uart("Device not ready \r\n");
		return 1;
	}

	/* configure interrupt and callback to receive data */
	int ret = uart_irq_callback_user_data_set(uart_dev, serial_cb, NULL);

	if (ret < 0) {
		if (ret == -ENOTSUP) {
			print_uart("Interrupt-driven UART API support not enabled\r\n");
		} else if (ret == -ENOSYS) {
			print_uart("UART device does not support interrupt-driven API\r\n");
		} else {
			print_uart("Error setting UART callback \r\n");
		}
		return 1;
	}
	uart_irq_rx_enable(uart_dev);
	
	return 0;
}


static void process_received_msg(char *msg_buf){
	
	// Check if wifi in message received [wifi:1]
        char* wifi_in_msg = strchr(msg_buf, 'w');
        if(*wifi_in_msg != NULL){
            const char wifi_status_char = (char)wifi_in_msg[5];
            const bool new_wifi_status = wifi_status_char == '1' ? true : false;
            set_wifi_status(new_wifi_status);
        }
        
        // Check if presence in message received [prs:1]
        char* presence_in_msg = strchr(msg_buf, 'p');
        if(*presence_in_msg != NULL){
            const char presence_status_char = (char)presence_in_msg[4];
            const bool new_presence_status = presence_status_char == '1' ? true : false;
            set_presence_status(new_presence_status);                
        }  

        // Check if electrical in message received [ele:1]
        char* ele_in_msg = strchr(msg_buf, 'e');
        if(*ele_in_msg != NULL){
            const char ele_status_char = (char)ele_in_msg[4];
            const bool new_ele_status = ele_status_char == '1' ? true : false;
            set_electrical_status(new_ele_status);
        }
}

void read_forever()
{
	print_uart("[LOG]: Reading UART for ever\r\n");

	char tx_buf[MSG_SIZE];

	/* indefinitely wait for input from the user */
	while (k_msgq_get(&uart_msgq, &tx_buf, K_FOREVER) == 0) {
		snprintf(tx_buff, sizeof(tx_buff), "%s%s\r\n", "[LOG]: UART message received: ", tx_buf);
    	print_uart(tx_buff);

        // Check if wifi in message received
        char* wifi_in_msg = strchr(tx_buf, 'w');
        if(*wifi_in_msg != NULL){
            const char wifi_status_char = (char)wifi_in_msg[5];
            const bool new_wifi_status = wifi_status_char == '1' ? true : false;
            set_wifi_status(new_wifi_status);
        }
        
        // Check if presence in message received
        char* presence_in_msg = strchr(tx_buf, 'p');
        if(*presence_in_msg != NULL){
            const char presence_status_char = (char)presence_in_msg[4];
            const bool new_presence_status = presence_status_char == '1' ? true : false;
            set_presence_status(new_presence_status);                
        }  

        // Check if electrical in message received
        char* ele_in_msg = strchr(tx_buf, 'e');
        if(*ele_in_msg != NULL){
            const char ele_status_char = (char)ele_in_msg[4];
            const bool new_ele_status = ele_status_char == '1' ? true : false;
            set_electrical_status(new_ele_status);
        }

        // Check if oulet in message received
        char* outlet_in_msg = strchr(tx_buf, 'o');
        if(*outlet_in_msg != NULL){
            const char r1_status_char = (char)outlet_in_msg[7];
            const char r2_status_char = (char)outlet_in_msg[8];
            const char r3_status_char = (char)outlet_in_msg[9];
            const char r4_status_char = (char)outlet_in_msg[10];

            const bool new_r1_status = r1_status_char == '1' ? true : false;
            const bool new_r2_status = r2_status_char == '1' ? true : false;
            const bool new_r3_status = r3_status_char == '1' ? true : false;
            const bool new_r4_status = r4_status_char == '1' ? true : false;
            set_power_strip_status(new_r1_status, new_r2_status, new_r3_status, new_r4_status);
        }
	}
}
```

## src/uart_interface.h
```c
#ifndef UART_INTERFACE_H
#define UART_INTERFACE_H

#include <zephyr/kernel.h>
#include <zephyr/device.h>
#include <zephyr/drivers/uart.h>
#include <string.h>

void serial_cb(const struct device *dev, void *user_data);
void print_uart(char *buf);
int init_uart();
void read_forever();
static void process_received_msg(char *msg_buf);

#endif
```
